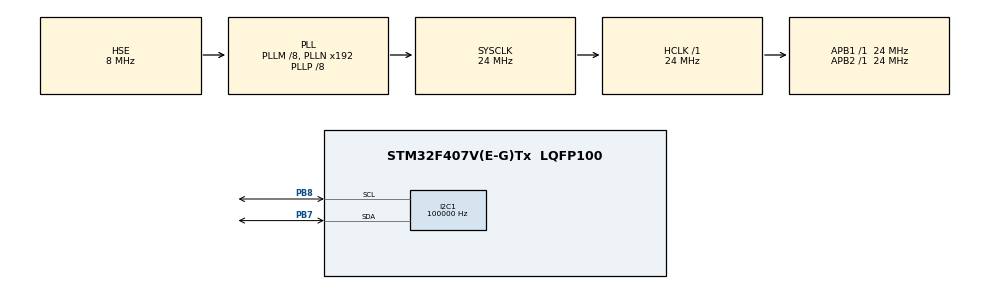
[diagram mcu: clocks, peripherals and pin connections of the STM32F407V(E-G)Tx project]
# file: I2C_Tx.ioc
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I2C1.ClockSpeed=100000
I2C1.I2C_Mode=I2C_Standard
Mcu.Family=STM32F4
Mcu.Name=STM32F407V(E-G)Tx
Mcu.Package=LQFP100
NVIC.PriorityGroup=NVIC_PRIORITYGROUP_4
PA13.Mode=Serial_Wire
PA13.Signal=SYS_JTMS-SWDIO
PA14.Mode=Serial_Wire
PA14.Signal=SYS_JTCK-SWCLK
PB7.GPIO_Speed=GPIO_SPEED_FREQ_MEDIUM
PB7.Mode=I2C
PB7.Signal=I2C1_SDA
PB8.GPIO_Speed=GPIO_SPEED_FREQ_MEDIUM
PB8.Mode=I2C
PB8.Signal=I2C1_SCL
PH0-OSC_IN.Mode=HSE-External-Oscillator
PH0-OSC_IN.Signal=RCC_OSC_IN
PH1-OSC_OUT.Mode=HSE-External-Oscillator
PH1-OSC_OUT.Signal=RCC_OSC_OUT
ProjectManager.HeapSize=0x200
ProjectManager.StackSize=0x400
ProjectManager.TargetToolchain=STM32CubeIDE
RCC.48MHZClocksFreq_Value=48000000
RCC.AHBFreq_Value=24000000
RCC.APB1Freq_Value=24000000
RCC.APB1TimFreq_Value=24000000
RCC.APB2Freq_Value=24000000
RCC.APB2TimFreq_Value=24000000
RCC.CortexFreq_Value=24000000
RCC.EnbaleCSS=true
RCC.HCLKFreq_Value=24000000
RCC.HSE_VALUE=8000000
RCC.HSI_VALUE=16000000
RCC.LSE_VALUE=32768
RCC.PLLM=8
RCC.PLLP=RCC_PLLP_DIV8
RCC.PLLSourceVirtual=RCC_PLLSOURCE_HSE
RCC.SYSCLKFreq_VALUE=24000000
RCC.SYSCLKSource=RCC_SYSCLKSOURCE_PLLCLK
RCC.VCOOutputFreq_Value=192000000
board=custom

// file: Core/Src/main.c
/* USER CODE BEGIN Header */
/*This project is a basic example of how to use I2C with PCF8574A port expander
 *We use pins PB7 and PB8 pins (SDA, SCL)
 *Microcontroller used is STM32F407VGT6*/
/**
  ******************************************************************************
  * @file           : main.c
  * @brief          : Main program body
  ******************************************************************************
  * @attention
  *
  * Copyright (c) 2024 STMicroelectronics.
  * All rights reserved.
  *
  * This software is licensed under terms that can be found in the LICENSE file
  * in the root directory of this software component.
  * If no LICENSE file comes with this software, it is provided AS-IS.
  *
  ******************************************************************************
  */
/* USER CODE END Header */
#include "main.h"

/* USER CODE BEGIN PD */
#define PCF8574A 0x70 //slave address

/* USER CODE END PD */

I2C_HandleTypeDef hi2c1;

void SystemClock_Config(void);
static void MX_GPIO_Init(void);
static void MX_I2C1_Init(void);

int main(void)
{
  /* USER CODE BEGIN 1 */
	uint8_t datos[2] = {0x7A, 0x08};

  /* USER CODE END 1 */

  /* MCU Configuration--------------------------------------------------------*/

  /* Reset of all peripherals, Initializes the Flash interface and the Systick. */
  HAL_Init();

  /* Configure the system clock */
  SystemClock_Config();

  /* Initialize all configured peripherals */
  MX_GPIO_Init();
  MX_I2C1_Init();

  /* Infinite loop */
  /* USER CODE BEGIN WHILE */
  while (1)
  {
	  //Send data through I2C1 to the PCF8574A
	  HAL_I2C_Master_Transmit(&hi2c1, PCF8574A, (uint8_t*)&datos[0], 1, 20);

	  HAL_Delay(1000);

	  HAL_I2C_Master_Transmit(&hi2c1, PCF8574A, (uint8_t*)&datos[1], 1, 20);

	  HAL_Delay(1000);

    /* USER CODE END WHILE */

  }
}

void SystemClock_Config(void)
{
  RCC_OscInitTypeDef RCC_OscInitStruct = {0};
  RCC_ClkInitTypeDef RCC_ClkInitStruct = {0};

  /** Configure the main internal regulator output voltage
  */
  __HAL_RCC_PWR_CLK_ENABLE();
  __HAL_PWR_VOLTAGESCALING_CONFIG(PWR_REGULATOR_VOLTAGE_SCALE1);

  /** Initializes the RCC Oscillators according to the specified parameters
  * in the RCC_OscInitTypeDef structure.
  */
  RCC_OscInitStruct.OscillatorType = RCC_OSCILLATORTYPE_HSE;
  RCC_OscInitStruct.HSEState = RCC_HSE_ON;
  RCC_OscInitStruct.PLL.PLLState = RCC_PLL_ON;
  RCC_OscInitStruct.PLL.PLLSource = RCC_PLLSOURCE_HSE;
  RCC_OscInitStruct.PLL.PLLM = 8;
  RCC_OscInitStruct.PLL.PLLN = 192;
  RCC_OscInitStruct.PLL.PLLP = RCC_PLLP_DIV8;
  RCC_OscInitStruct.PLL.PLLQ = 4;
  if (HAL_RCC_OscConfig(&RCC_OscInitStruct) != HAL_OK)
  {
    Error_Handler();
  }

  /** Initializes the CPU, AHB and APB buses clocks
  */
  RCC_ClkInitStruct.ClockType = RCC_CLOCKTYPE_HCLK|RCC_CLOCKTYPE_SYSCLK
                              |RCC_CLOCKTYPE_PCLK1|RCC_CLOCKTYPE_PCLK2;
  RCC_ClkInitStruct.SYSCLKSource = RCC_SYSCLKSOURCE_PLLCLK;
  RCC_ClkInitStruct.AHBCLKDivider = RCC_SYSCLK_DIV1;
  RCC_ClkInitStruct.APB1CLKDivider = RCC_HCLK_DIV1;
  RCC_ClkInitStruct.APB2CLKDivider = RCC_HCLK_DIV1;

  if (HAL_RCC_ClockConfig(&RCC_ClkInitStruct, FLASH_LATENCY_0) != HAL_OK)
  {
    Error_Handler();
  }

  /** Enables the Clock Security System
  */
  HAL_RCC_EnableCSS();
}

static void MX_I2C1_Init(void)
{

  hi2c1.Instance = I2C1;
  hi2c1.Init.ClockSpeed = 100000;
  hi2c1.Init.DutyCycle = I2C_DUTYCYCLE_2;
  hi2c1.Init.OwnAddress1 = 0;
  hi2c1.Init.AddressingMode = I2C_ADDRESSINGMODE_7BIT;
  hi2c1.Init.DualAddressMode = I2C_DUALADDRESS_DISABLE;
  hi2c1.Init.OwnAddress2 = 0;
  hi2c1.Init.GeneralCallMode = I2C_GENERALCALL_DISABLE;
  hi2c1.Init.NoStretchMode = I2C_NOSTRETCH_DISABLE;
  if (HAL_I2C_Init(&hi2c1) != HAL_OK)
  {
    Error_Handler();
  }

}

static void MX_GPIO_Init(void)
{
  GPIO_InitTypeDef GPIO_InitStruct = {0};

  /* GPIO Ports Clock Enable */
  __HAL_RCC_GPIOE_CLK_ENABLE();
  __HAL_RCC_GPIOC_CLK_ENABLE();
  __HAL_RCC_GPIOH_CLK_ENABLE();
  __HAL_RCC_GPIOA_CLK_ENABLE();
  __HAL_RCC_GPIOB_CLK_ENABLE();
  __HAL_RCC_GPIOD_CLK_ENABLE();

  /*Configure GPIO pins : PE2 PE3 PE4 PE5
                           PE6 PE7 PE8 PE9
                           PE10 PE11 PE12 PE13
                           PE14 PE15 PE0 PE1 */
  GPIO_InitStruct.Pin = GPIO_PIN_2|GPIO_PIN_3|GPIO_PIN_4|GPIO_PIN_5
                          |GPIO_PIN_6|GPIO_PIN_7|GPIO_PIN_8|GPIO_PIN_9
                          |GPIO_PIN_10|GPIO_PIN_11|GPIO_PIN_12|GPIO_PIN_13
                          |GPIO_PIN_14|GPIO_PIN_15|GPIO_PIN_0|GPIO_PIN_1;
  GPIO_InitStruct.Mode = GPIO_MODE_ANALOG;
  GPIO_InitStruct.Pull = GPIO_NOPULL;
  HAL_GPIO_Init(GPIOE, &GPIO_InitStruct);

  /*Configure GPIO pins : PC13 PC14 PC15 PC0
                           PC1 PC2 PC3 PC4
                           PC5 PC6 PC7 PC8
                           PC9 PC10 PC11 PC12 */
  GPIO_InitStruct.Pin = GPIO_PIN_13|GPIO_PIN_14|GPIO_PIN_15|GPIO_PIN_0
                          |GPIO_PIN_1|GPIO_PIN_2|GPIO_PIN_3|GPIO_PIN_4
                          |GPIO_PIN_5|GPIO_PIN_6|GPIO_PIN_7|GPIO_PIN_8
                          |GPIO_PIN_9|GPIO_PIN_10|GPIO_PIN_11|GPIO_PIN_12;
  GPIO_InitStruct.Mode = GPIO_MODE_ANALOG;
  GPIO_InitStruct.Pull = GPIO_NOPULL;
  HAL_GPIO_Init(GPIOC, &GPIO_InitStruct);

  /*Configure GPIO pins : PA0 PA1 PA2 PA3
                           PA4 PA5 PA6 PA7
                           PA8 PA9 PA10 PA11
                           PA12 PA15 */
  GPIO_InitStruct.Pin = GPIO_PIN_0|GPIO_PIN_1|GPIO_PIN_2|GPIO_PIN_3
                          |GPIO_PIN_4|GPIO_PIN_5|GPIO_PIN_6|GPIO_PIN_7
                          |GPIO_PIN_8|GPIO_PIN_9|GPIO_PIN_10|GPIO_PIN_11
                          |GPIO_PIN_12|GPIO_PIN_15;
  GPIO_InitStruct.Mode = GPIO_MODE_ANALOG;
  GPIO_InitStruct.Pull = GPIO_NOPULL;
  HAL_GPIO_Init(GPIOA, &GPIO_InitStruct);

  /*Configure GPIO pins : PB0 PB1 PB2 PB10
                           PB11 PB12 PB13 PB14
                           PB15 PB3 PB4 PB5
                           PB6 PB9 */
  GPIO_InitStruct.Pin = GPIO_PIN_0|GPIO_PIN_1|GPIO_PIN_2|GPIO_PIN_10
                          |GPIO_PIN_11|GPIO_PIN_12|GPIO_PIN_13|GPIO_PIN_14
                          |GPIO_PIN_15|GPIO_PIN_3|GPIO_PIN_4|GPIO_PIN_5
                          |GPIO_PIN_6|GPIO_PIN_9;
  GPIO_InitStruct.Mode = GPIO_MODE_ANALOG;
  GPIO_InitStruct.Pull = GPIO_NOPULL;
  HAL_GPIO_Init(GPIOB, &GPIO_InitStruct);

  /*Configure GPIO pins : PD8 PD9 PD10 PD11
                           PD12 PD13 PD14 PD15
                           PD0 PD1 PD2 PD3
                           PD4 PD5 PD6 PD7 */
  GPIO_InitStruct.Pin = GPIO_PIN_8|GPIO_PIN_9|GPIO_PIN_10|GPIO_PIN_11
                          |GPIO_PIN_12|GPIO_PIN_13|GPIO_PIN_14|GPIO_PIN_15
                          |GPIO_PIN_0|GPIO_PIN_1|GPIO_PIN_2|GPIO_PIN_3
                          |GPIO_PIN_4|GPIO_PIN_5|GPIO_PIN_6|GPIO_PIN_7;
  GPIO_InitStruct.Mode = GPIO_MODE_ANALOG;
  GPIO_InitStruct.Pull = GPIO_NOPULL;
  HAL_GPIO_Init(GPIOD, &GPIO_InitStruct);

}

void Error_Handler(void)
{
  __disable_irq();
  while (1)
  {
  }
}
